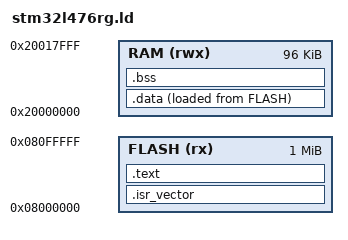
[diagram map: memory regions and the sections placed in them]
ENTRY(Reset_Handler)

MEMORY {
  FLASH (rx)  : ORIGIN = 0x08000000, LENGTH = 1024K
  RAM   (rwx) : ORIGIN = 0x20000000, LENGTH = 96K
}

/* The server validates the vector's stack value as an in-range writable word. */
_estack = ORIGIN(RAM) + LENGTH(RAM) - 4;

SECTIONS {
  .isr_vector : { KEEP(*(.isr_vector)) } > FLASH
  .text : { *(.text*) *(.rodata*) } > FLASH
  .data : { *(.data*) } > RAM AT > FLASH
  .bss (NOLOAD) : { *(.bss*) *(COMMON) } > RAM
}
